# SF32LB57x register map
File version: 1.0
CPU: CM33 r0p1, little endian, MPU, FPU, 3 interrupt priority bits
Registers are 32-bit, read-write, reset 0x0 unless marked. A register's access mark holds for its fields unless they carry their own. Offsets are from the block's base; [hi:lo] are bit positions; {n}, {i} and the like mark numbered series; 'fields as' and 'values as' point back to an identical list.

## LCDC1
Base 0x50008000
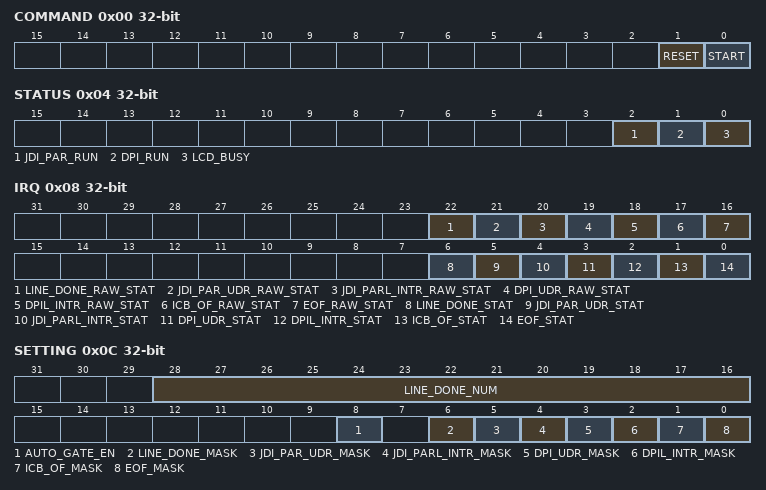
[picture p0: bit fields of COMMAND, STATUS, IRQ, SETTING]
0x00 COMMAND
  [1] RESET — 1: reset the whole graphics 0: release the reset
  [0] START — write 1 to trigger the lcd interface block
0x04 STATUS
  [2] JDI_PAR_RUN — JDI parallel interface is running
  [1] DPI_RUN — DPI interface is running
  [0] LCD_BUSY — LCS controll busy flag
0x08 IRQ
  [22] LINE_DONE_RAW_STAT — raw_status of line process done interrupt
  [21] JDI_PAR_UDR_RAW_STAT — raw_status of jdi parallel interface under run interrupt
  [20] JDI_PARL_INTR_RAW_STAT — raw_status of jdi parallel interface line interrupt
  [19] DPI_UDR_RAW_STAT — raw status of dpi under run interrupt
  [18] DPIL_INTR_RAW_STAT — raw status of dpi line interrupt
  [17] ICB_OF_RAW_STAT — raw status of icb overflow interrupt
  [16] EOF_RAW_STAT — raw status of end of frame interrupt
  [6] LINE_DONE_STAT — line process done interrupt, masked by mask register
  [5] JDI_PAR_UDR_STAT — jdi parallel interface under run interrupt, masked by mask register
  [4] JDI_PARL_INTR_STAT — jdi parallel interface line interrupt, masked by mask register
  [3] DPI_UDR_STAT — dpi under run interrupt, masked by mask register
  [2] DPIL_INTR_STAT — dpi line interrupt, masked by mask register
  [1] ICB_OF_STAT — icb overflow interrupt, masked by mask register
  [0] EOF_STAT — end of frame interrupt, masked by mask register
0x0C SETTING
  [28:16] LINE_DONE_NUM — line number of line process done interrupt
  [8] AUTO_GATE_EN — auto clock gating enable
  [6] LINE_DONE_MASK — line process done interrupt, 0: mask the interrupt
  [5] JDI_PAR_UDR_MASK — jdi parallel interface under run interrupt mask, 0: mask the interrupt
  [4] JDI_PARL_INTR_MASK — jdi parallel interface line interrupt, 0: mask the interrupt
  [3] DPI_UDR_MASK — dpi under run interrupt mask, 0: mask the interrupt
  [2] DPIL_INTR_MASK — dpi line interrupt, 0: mask the interrupt
  [1] ICB_OF_MASK — icb overflow interrupt mask, 0: mask the interrupt
  [0] EOF_MASK — end of frame interrupt mask, 0: mask the interrupt
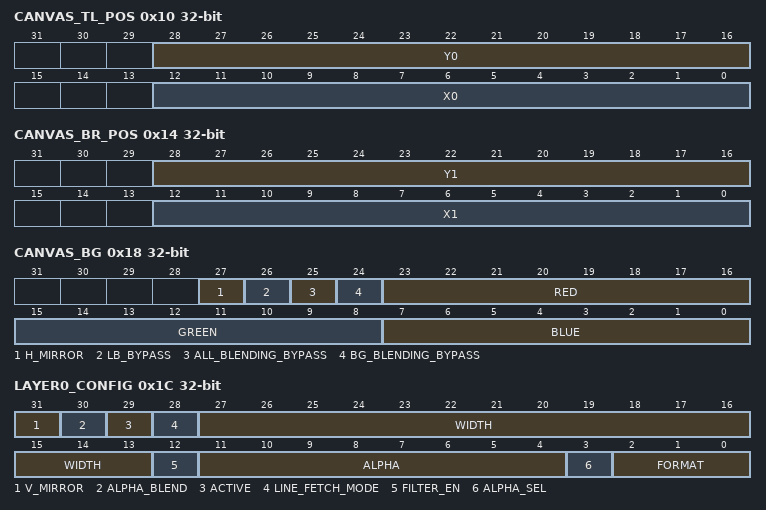
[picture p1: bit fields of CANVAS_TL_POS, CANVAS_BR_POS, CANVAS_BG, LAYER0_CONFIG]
0x10 CANVAS_TL_POS
  [28:16] Y0, [12:0] X0
0x14 CANVAS_BR_POS
  [28:16] Y1, [12:0] X1
0x18 CANVAS_BG
  [27] H_MIRROR — set 1 to do horizontal mirror for output image(not supported)
  [26] LB_BYPASS — line buffer bypass. Set 1 to bypass line buffer.
  [25] ALL_BLENDING_BYPASS — if this bit is set, lcdc is in pure dma mode. No blending operation.
  [24] BG_BLENDING_BYPASS — if this bit is set, the layer is not blending with background. The alpha value will be reserved to output.
  [23:16] RED — Red color
  [15:8] GREEN — green color
  [7:0] BLUE — blue color
0x1C LAYER0_CONFIG
  [31] V_MIRROR — set 1 to do vertical mirror for the layer
  [30] ALPHA_BLEND — set 1 to enable alpha blending mode. Use layer alpha as blending factor for image with Alpha. Alpha_out = Layer_alpha * Image_alpha
  [29] ACTIVE — layer active flag
  [28] LINE_FETCH_MODE — line fetch mode 0: address skip every single line 1: address skip every two line
  [27:13] WIDTH — source image width(including padding), unit is bytes
  [12] FILTER_EN — layer color filter enable
  [11:4] ALPHA — layer alpha value
  [3] ALPHA_SEL — alpha selection 1'b0: select alpha according to image format 1'b1: select layer alpha
  [2:0] FORMAT — overlay layer input format 3'h0: RGB565 3'h1: RGB888 3'h2: ARGB8888 3'h3: ARGB8565 3'h4: RGB332 3'h5: A8 3'h6: L8 others: reserved
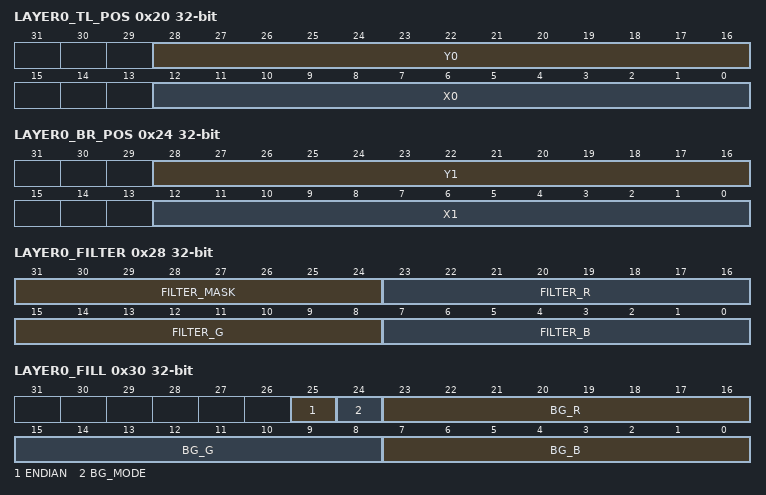
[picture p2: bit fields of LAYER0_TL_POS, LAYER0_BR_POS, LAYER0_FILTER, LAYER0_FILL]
0x20 LAYER0_TL_POS
  [28:16] Y0 — Coordingate Y-value
  [12:0] X0 — Coordinate X-value
0x24 LAYER0_BR_POS
  [28:16] Y1 — Coordingate Y-value
  [12:0] X1 — Coordinate X-value
0x28 LAYER0_FILTER
  [31:24] FILTER_MASK — layer color filter mask
  [23:16] FILTER_R — filter r color
  [15:8] FILTER_G — filter g color
  [7:0] FILTER_B — filter b color
0x2C LAYER0_SRC
  [31:0] ADDR — source image RGB data address[31:0]. For RGB565 format, address should be aligned to halfword. For ARGB8888 format, address should be aligned to word.
0x30 LAYER0_FILL
  [25] ENDIAN — input 565 data format endian 0: {R[4:0], G[5:3], G[2:0], B[4:0]} 1: {G[2:0], R[4:0], B[4:0], G[5:3]}
  [24] BG_MODE — not used
  [23:16] BG_R — background r color
  [15:8] BG_G — background g color
  [7:0] BG_B — background b color
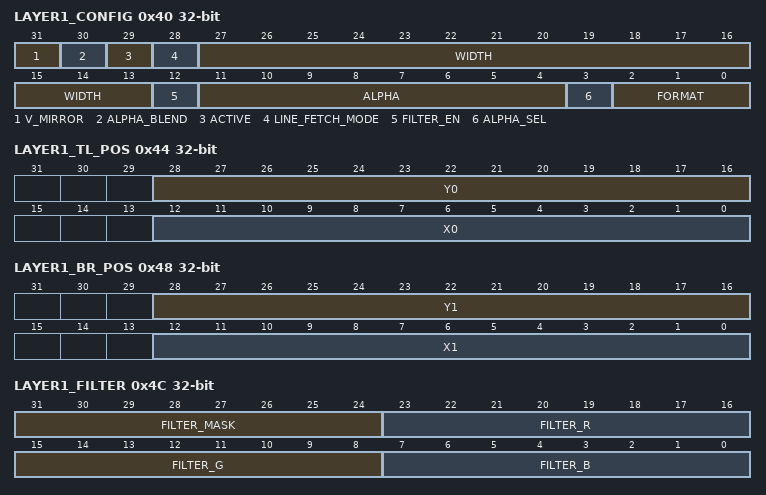
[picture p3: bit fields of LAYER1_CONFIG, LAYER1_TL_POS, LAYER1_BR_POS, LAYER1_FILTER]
0x40 LAYER1_CONFIG
  fields as LAYER0_CONFIG
0x44 LAYER1_TL_POS
  [28:16] Y0 — Coordingate Y-value
  [12:0] X0 — Coordinate X-value
0x48 LAYER1_BR_POS
  [28:16] Y1 — Coordingate Y-value
  [12:0] X1 — Coordinate X-value
0x4C LAYER1_FILTER
  fields as LAYER0_FILTER
0x50 LAYER1_SRC
  fields as LAYER0_SRC
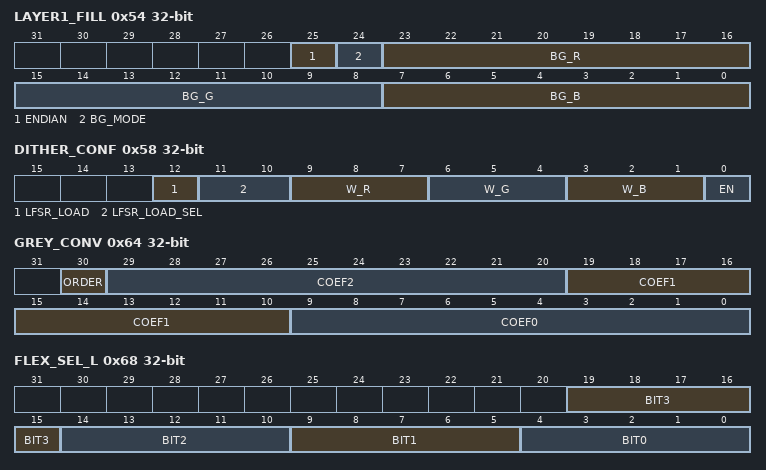
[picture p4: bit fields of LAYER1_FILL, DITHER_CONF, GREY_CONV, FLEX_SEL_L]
0x54 LAYER1_FILL
  fields as LAYER0_FILL
0x58 DITHER_CONF
  [12] LFSR_LOAD — load lfsr init value
  [11:10] LFSR_LOAD_SEL — select lfsr 0: none 1: red 2: green 3: blue
  [9:7] W_R — red dither width
  [6:4] W_G — green dither width
  [3:1] W_B — blue dither width
  [0] EN — dither enable
0x5C DITHER_LFSR
  [31:0] INIT_VAL — lfsr init load value
0x60 CONV_CFG
  [2:0] FORMAT — CANVAS conversion format: 0: ARGB 1: G8 2: G4 3: G2 4: F8 5: F4 6: F2
0x64 GREY_CONV
  [30] ORDER — G4 format bit order 1'h0: byteG4 = {p1, p0}, byteG2 = {p3,p2,p1,p0} 1'h1: byteG4 = {p0, p1}, byteG2 = {p0,p1,p2,p3}
  [29:20] COEF2
  [19:10] COEF1
  [9:0] COEF0 — grey = (coef0 * r + coef1 * g + coef2 * b) >> 10
0x68 FLEX_SEL_L
  [19:15] BIT3
  [14:10] BIT2
  [9:5] BIT1
  [4:0] BIT0 — bit select index from internal ARGB8888 format data
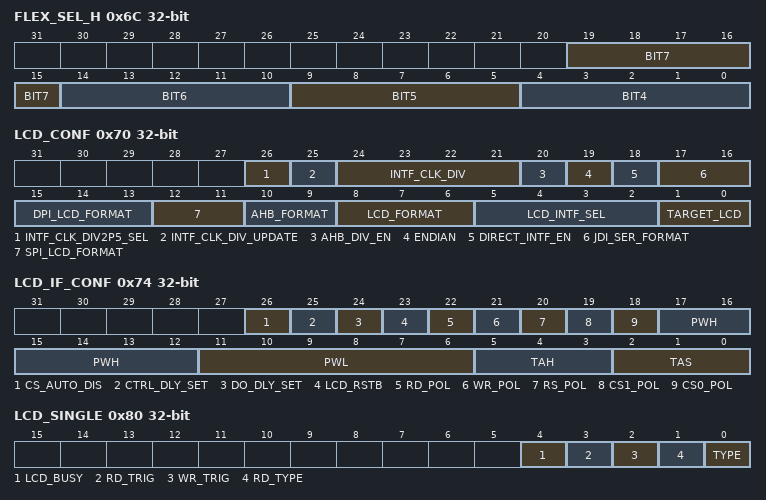
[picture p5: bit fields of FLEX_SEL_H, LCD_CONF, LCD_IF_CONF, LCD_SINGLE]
0x6C FLEX_SEL_H
  [19:15] BIT7
  [14:10] BIT6
  [9:5] BIT5
  [4:0] BIT4 — bit select index from internal ARGB8888 format data
0x70 LCD_CONF
  [26] INTF_CLK_DIV2P5_SEL — write 1 to select 2.5 divider value for interface clock
  [25] INTF_CLK_DIV_UPDATE — write 1 to update lcd interface clock divider value.
  [24:21] INTF_CLK_DIV — lcd interface clock divider value. minimum value is 1.
  [20] AHB_DIV_EN — set 1 to divide AHB undefined length burst to fix length burst
  [19] ENDIAN — LCD 565 data format endian, this bit would affect SPI, DPI, DBI and AHB interface 565 format 0: {R[4:0], G[5:3], G[2:0], B[4:0]} 1: {G[2:0], R[4:0], B[4:0], G[5:3]}
  [18] DIRECT_INTF_EN — when the target LCD is AHB LCD, this bit enable the direct interface to DSI module. Direct interface has higher bandwidth and speed than AHB interface.
  [17:16] JDI_SER_FORMAT — JDI serial format 2'b00: 3-bit mode 2'b01: 4-bit mode 2'b10: 1-bit mode 2'b11: reserved
  [15:13] DPI_LCD_FORMAT — DPI LCD format 3'b000: 16-bit conf1 3'b001: 16-bit conf2 3'b010: 16-bit conf3 3'b011: 18-bit conf1 3'b100: 18-bit conf2 3'b101: 24-bit 3'b110: 18-bit over 8-bit bus 3'b111: 24-bit over 8-bit bus others: Reserved
  [12:11] SPI_LCD_FORMAT — SPI LCD format 2'b00: 8-bit RGB 3:3:2 2'b01: 16-bit RGB 5:6:5 2'b10: 24-bit RGB 8:8:8 2'b11: 8-bit mode(lowest 8 bit mode)
  [10:9] AHB_FORMAT — AHB LCD/RAM output format: 0: RGB565 1: RGB888 2: ARGB8888 3: RGB332
  [8:6] LCD_FORMAT — LCD output format: 3'b000: 8-bit RGB 3:3:2 3'b001: 16-bit RGB 5:6:5 over 8-bit bus, 2 cycles/pixel 3'b010: 12-bit RGB 4:4:4 3'b011: 16-bit RGB 5:6:5 3'b100: 18-bit RGB 6:6:6 3'b101: 24-bit RGB 8:8:8 3'b110: 24-bit RGB 8:8:8 over 16-bit bus, 1.5 cycles/pixel 3'b111: 24-bit RGB 8:8:8 over 8-bit bus, 3cycles/pixel others: Reserved
  [5:2] LCD_INTF_SEL — 4'h0: 8080 DBI Type B 4'h1: SPI interface 4'h2: DBI to DSI interface 4'h3: DPI interface 4'h4: JDI serial interface 4'h5: JDI parallel interface 4'h6: 8080 DBI Type A 4'h7: DPI to DSI interface 4'h8: Timing Controller Interface other: reserved
  [1:0] TARGET_LCD — The Data can be sent to four destinations: 2'b00: LCD panel 0 2'b01: LCD panel 1 2'b10: AHB LCD 2'b11: AHB RAM
0x74 LCD_IF_CONF
  [26] CS_AUTO_DIS — 1: CS is automatically disabled after data transaction 0: CS is not disabled after data transaction
  [25] CTRL_DLY_SET — if this bit is set to 1, LCD control output will be delayed for 1 lcdc clock cycle
  [24] DO_DLY_SET — if this bit is set to 1, LCD data output will be delayed for 1 lcdc clock cycle
  [23] LCD_RSTB — LCD RSTB pin, direct to output
  [22] RD_POL — LCD RD pin polarity. RD is 0 for write operation, 1 for idle if polarity bit is set as 0. RD bit definition is opposite if polarity bit is set as 1.
  [21] WR_POL — LCD WR pin polarity. WR is 0 for write operation, 1 for idle if polarity bit is set as 0. WR bit definition is opposite if polarity bit is set as 1.
  [20] RS_POL — LCD RS pin polarity. RS is 1 for data access, 0 for command access if polarity bit is set as 0. RS bit definition is opposite if polarity bit is set as 1.
  [19] CS1_POL — LCD0 CS pin polarity. CS is 0 for LCD chip select if polarity bit is set as 0. CS bit definition is opposite if polarity bit is set as 1.
  [18] CS0_POL — LCD1 CS pin polarity. CS is 0 for LCD chip select if polarity bit is set as 0. CS bit definition is opposite if polarity bit is set as 1.
  [17:12] PWH — inactive cycles of LCD_WR/LCD_RD for consecutive write/read operation
  [11:6] PWL — active cycles of LCD_WR/LCD_RD
  [5:3] TAH — hold cycles, delay from LCD_WR/LCD_RD inactive to LCD_CS inactive
  [2:0] TAS — setup cycles, delay from LCD_CS active to LCD_WR/LCD_RD active
0x78 LCD_MEM
  [31:0] ADDR — address for AHB LCD/AHB RAM
0x7C LCD_O_WIDTH
  [15:0] OFFSET — AHB RAM address offset for each line
0x80 LCD_SINGLE
  [4] LCD_BUSY — LCD/SPI LCD interface is busy for single access
  [3] RD_TRIG — Single read operation trigger
  [2] WR_TRIG — Single write operation trigger
  [1] RD_TYPE — LCD access type during read data phase 1'h0: command 1'h1: data
  [0] TYPE — LCD access type, this bit could affect all LCD interface including SPI, parellel and AHB 1'b0: command 1'b1: data
0x84 LCD_WR
  [31:0] DATA — LCD write data
0x88 LCD_RD
  [31:0] DATA — LCD read data
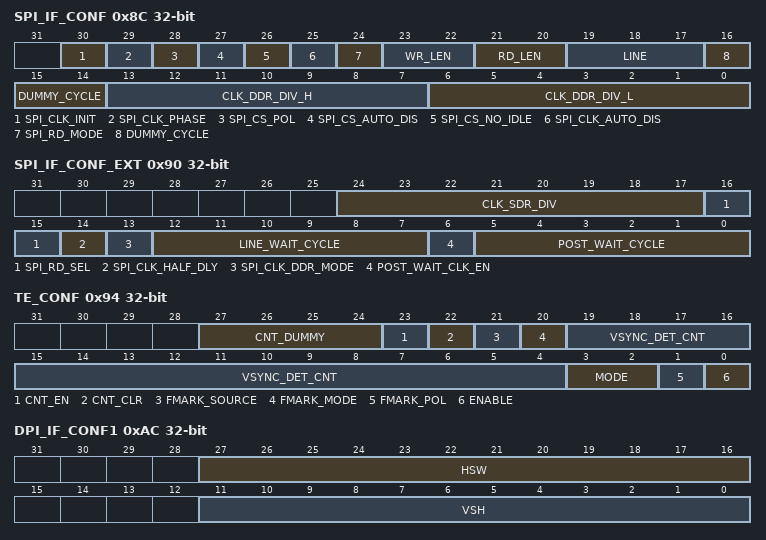
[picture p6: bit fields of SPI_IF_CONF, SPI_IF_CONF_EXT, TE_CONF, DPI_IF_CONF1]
0x8C SPI_IF_CONF
  [30] SPI_CLK_INIT — SPI CLK idle state value 1'h0: high 1'h1: low
  [29] SPI_CLK_PHASE — SPI CLK phase 1'h0: 1st edge for data capture 1'h1: 2nd edge for data capture
  [28] SPI_CS_POL — SPI CS polarity 0: low active 1: high active
  [27] SPI_CS_AUTO_DIS — 1: SPI CS is automatically disabled after data transaction 0: SPI CS is not disabled after data transaction
  [26] SPI_CS_NO_IDLE — 1: SPI CS is always active during data transaction 0: SPI CS is IDLE in wait state during data transaction
  [25] SPI_CLK_AUTO_DIS — 1: SPI clock auto disable in wait state during data transaction 0: SPI clock is always on in wait state during data transaction
  [24] SPI_RD_MODE — SPI read mode: 1'b0: normal read. Send write request before read. 1'b1: direct read. Read data without write request.
  [23:22] WR_LEN — SPI write data length(single access)
  [21:20] RD_LEN — SPI read data length(single access)
  [19:17] LINE — SPI line mode 0: 4-line 1: 4-line with 2 data line(support RGB565 and RGB888) 2: 4-line with 4 data line(support RGB565 and RGB888) 3: reserved 4: 3-line 5: 3-line with 2 data line(support RGB565 and RGB888) 6: 3-line with 4 data line(support RGB565 and RGB888) 7: reserved
  [16:14] DUMMY_CYCLE — SPI transaction dummy cycle
  [13:7] CLK_DDR_DIV_H — SPI clock ddr mode divider high cycle count, minimum value is 1
  [6:0] CLK_DDR_DIV_L — SPI clock ddr mode divider low cycle count, minimum value is 1
0x90 SPI_IF_CONF_EXT
  [24:17] CLK_SDR_DIV — SPI clock sdr mode divider value, minimum value is 1.
  [16:15] SPI_RD_SEL — SPI read line select. 0: select line 0 1: select line 1 2: select line 2 3: select line 3
  [14] SPI_CLK_HALF_DLY — delay SPI clock for half lcd clock. This option is used for odd spi clock divider value.
  [13] SPI_CLK_DDR_MODE — SPI CLK DDR mode 1'h0: SDR mode 1'h1: DDR mode
  [12:7] LINE_WAIT_CYCLE — SPI line wait cycle, wait cycle is after each line and is according to SPI clock. 0 refers to no wait cycle.
  [6] POST_WAIT_CLK_EN — SPI clock enable during post wait cycle
  [5:0] POST_WAIT_CYCLE — SPI wait cycle after last pixel, wait cycle is according to SPI clock. 0 refers to no wait cycle.
0x94 TE_CONF
  [27:24] CNT_DUMMY — dummy TE triggers after CNT_EN is set. Skip the first CNT_DUMMY TE triggers, then start TE counter.
  [23] CNT_EN — enable TE counter for window mode
  [22] CNT_CLR — clear TE counter for window mode
  [21] FMARK_SOURCE — TE signal source 1: use TE signal from DSI 0: use TE signal from external pin
  [20] FMARK_MODE — TE signal trigger mode 1: edge trigger 0: pulse trigger
  [19:4] VSYNC_DET_CNT — vsync signal detect counter, used for mode 1 to detect vsync signal
  [3:2] MODE — 0: vsync only TE mode 1: vsync+hsync TE mode 2: window TE mode
  [1] FMARK_POL — TE signal polarity
  [0] ENABLE — TE enable
0x98 TE_CONF2
  [31:0] DLY_CNT0 — TE delay counter0, used for vsync and vsync+hsync mode
0x9C TE_CONF3
  [31:0] DLY_CNT1 — TE delay counter1, used for window mode TE window is active when (te_cnt lte cnt0 || te_cnt >= cnt1) and and te_cnt >= cnt2
0xA0 TE_CONF4
  [31:0] DLY_CNT2 — TE delay counter2, used for window mode TE window is active when (te_cnt lte cnt0 || te_cnt >= cnt1) and and te_cnt >= cnt2
0xA4 TE_STAT
  [31:0] TE_C_CNT — current TE counter for window mode
0xA8 TE_STAT2
  [31:0] TE_MAX_CNT — max TE counter value for window mode
0xAC DPI_IF_CONF1
  [27:16] HSW — dpi hsync width
  [11:0] VSH — dpi vsync height
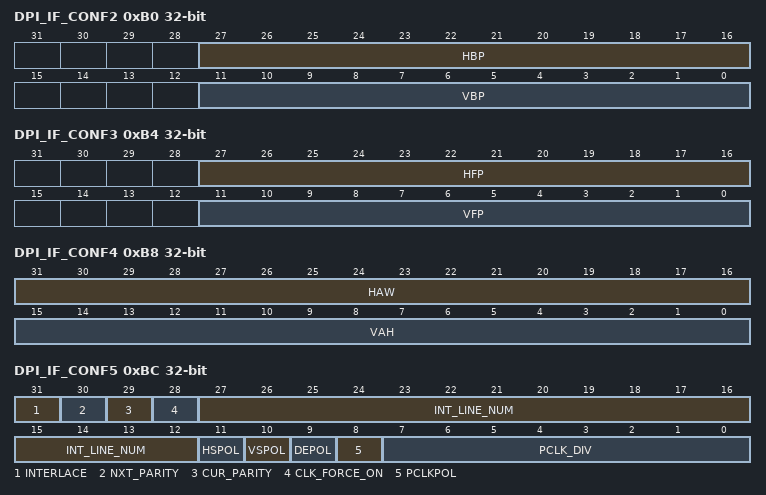
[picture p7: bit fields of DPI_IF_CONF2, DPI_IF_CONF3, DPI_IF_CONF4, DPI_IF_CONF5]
0xB0 DPI_IF_CONF2
  [27:16] HBP — horizontal back porch
  [11:0] VBP — vertical back porch
0xB4 DPI_IF_CONF3
  [27:16] HFP — horizontal front porch
  [11:0] VFP — vertical front porch
0xB8 DPI_IF_CONF4
  [31:16] HAW — horizontal active width
  [15:0] VAH — vertical active height
0xBC DPI_IF_CONF5
  [31] INTERLACE — 1: interlace mode 0: non interlace mode
  [30] NXT_PARITY — parity for next frame in interlace mode 1: odd 0: even
  [29] CUR_PARITY — parity for current frame in interlace mode 1: odd 0: even
  [28] CLK_FORCE_ON — 1: force DPI clock on 0: DPI clock is controlled by hardware
  [27:12] INT_LINE_NUM — DPI interrupt line number
  [11] HSPOL — hsync polarity
  [10] VSPOL — vsync polarity
  [9] DEPOL — de polarity
  [8] PCLKPOL — pixel clock polarity
  [7:0] PCLK_DIV — pixel clock divider(minimum is 2)
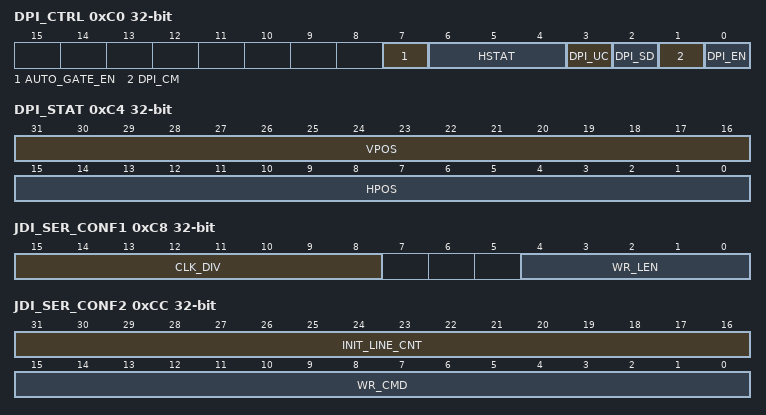
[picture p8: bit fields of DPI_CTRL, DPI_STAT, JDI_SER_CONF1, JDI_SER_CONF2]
0xC0 DPI_CTRL
  [7] AUTO_GATE_EN — dpi clock auto gating when underrun is detected 1: enable dpi clock auto gating function 0: disable dpi clock auto gating function
  [6:4] HSTAT — horizontal status 0: idle 1: prep 2: hsync 3: hbp 4: hact 5: hfp 6: wait
  [3] DPI_UC — dpi update config
  [2] DPI_SD — dpi shutdown
  [1] DPI_CM — dpi color mode
  [0] DPI_EN — dpi interface enable
0xC4 DPI_STAT
  [31:16] VPOS — dpi vertical position
  [15:0] HPOS — dpi horizontal position
0xC8 JDI_SER_CONF1
  [15:8] CLK_DIV — jdi serial clock divider(minimum is 2)
  [4:0] WR_LEN — jdi single write bit length
0xCC JDI_SER_CONF2
  [31:16] INIT_LINE_CNT — jdi serial init line counter
  [15:0] WR_CMD — jdi serial data transfer write command
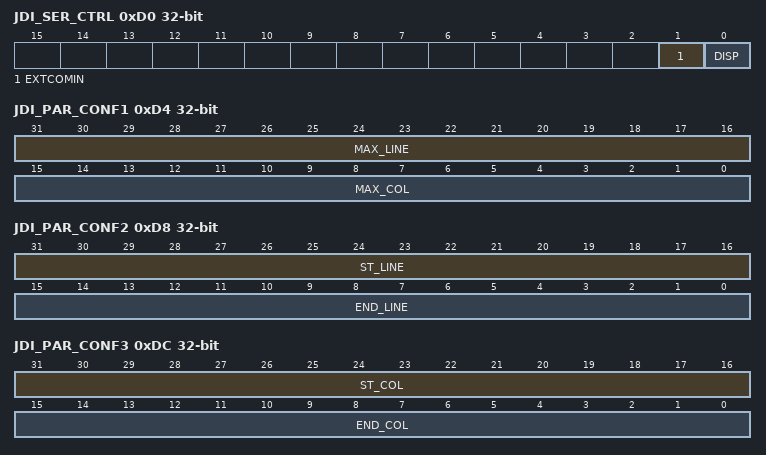
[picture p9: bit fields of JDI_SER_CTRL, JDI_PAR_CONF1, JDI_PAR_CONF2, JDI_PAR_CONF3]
0xD0 JDI_SER_CTRL
  [1] EXTCOMIN — jdi serial interface extcomin control
  [0] DISP — jdi serial interface disp control
0xD4 JDI_PAR_CONF1
  [31:16] MAX_LINE — jdi parallel interface max line, line number start from 0
  [15:0] MAX_COL — jdi parallel interface max column, column number start from 0
0xD8 JDI_PAR_CONF2
  [31:16] ST_LINE — jdi parallel interface start line, line number start from 0
  [15:0] END_LINE — jdi parallel interface end line, line number start from 0
0xDC JDI_PAR_CONF3
  [31:16] ST_COL — jdi parallel interface start column, column number start from 0
  [15:0] END_COL — jdi parallel interface end column, column number start from 0
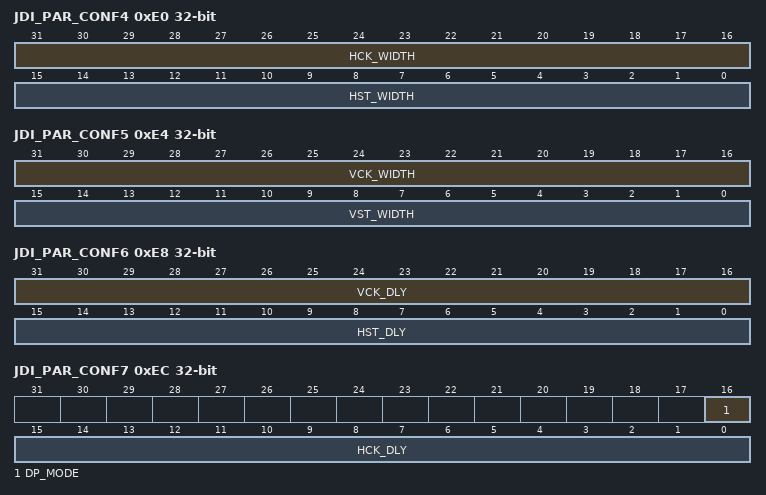
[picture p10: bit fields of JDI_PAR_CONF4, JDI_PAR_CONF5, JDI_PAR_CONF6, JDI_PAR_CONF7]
0xE0 JDI_PAR_CONF4
  [31:16] HCK_WIDTH — jdi parallel interface HCK width, HSK width = lcd_ck_cycle * HCK_WIDTH
  [15:0] HST_WIDTH — jdi parallel interface HST width, HST width = lcd_ck_cycle * HST_WIDTH
0xE4 JDI_PAR_CONF5
  [31:16] VCK_WIDTH — jdi parallel interface VCK width, VCK width = lcd_ck_cycle * VCK_WIDTH
  [15:0] VST_WIDTH — jdi parallel interface VST width, VST width = lcd_ck_cycle * VST_WIDTH
0xE8 JDI_PAR_CONF6
  [31:16] VCK_DLY — jdi parallel interface VST to VCK delay, VST2VCK delay = lcd_ck_cycle * VCK_DLY
  [15:0] HST_DLY — jdi parallel interface VCK to HST delay, VCK2HST delay = lcd_ck_cycle * HST_DLY
0xEC JDI_PAR_CONF7
  [16] DP_MODE — double pixel mode. Some jdi parallel screens use large pixel+small pixel structure. Set this bit to 1 to support this structure.
  [15:0] HCK_DLY — jdi parallel interface HST to HCK delay
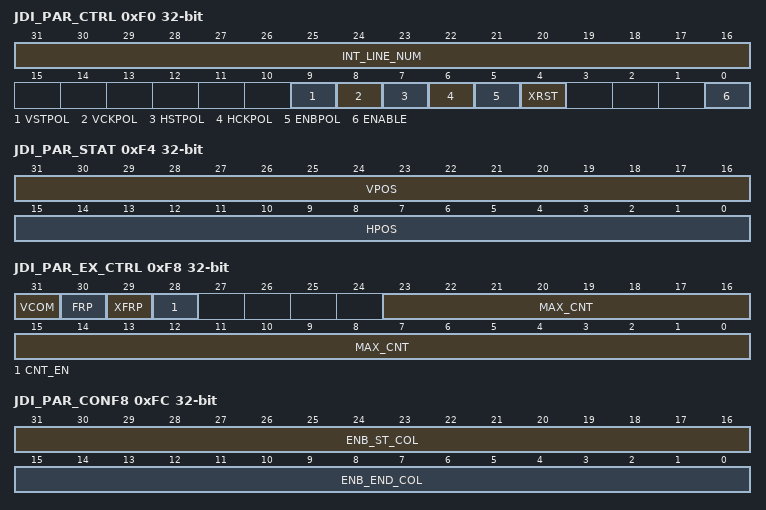
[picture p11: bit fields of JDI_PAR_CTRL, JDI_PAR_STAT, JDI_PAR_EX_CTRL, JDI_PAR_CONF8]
0xF0 JDI_PAR_CTRL
  [31:16] INT_LINE_NUM — jdi parallel interface interrupt line number, line number start from 0.
  [9] VSTPOL — jdi parallel vst polarity
  [8] VCKPOL — jdi parallel vck polarity
  [7] HSTPOL — jdi parallel hst polarity
  [6] HCKPOL — jdi parallel hck polarity
  [5] ENBPOL — jdi parallel enb polarity
  [4] XRST — jdi parallel interface XRST
  [0] ENABLE — jdi parallel interface enable
0xF4 JDI_PAR_STAT
  [31:16] VPOS — jdi parallel vertical position
  [15:0] HPOS — jdi parallel horizontal position
0xF8 JDI_PAR_EX_CTRL
  [31] VCOM — VCOM value
  [30] FRP — FRP value
  [29] XFRP — XFRP value
  [28] CNT_EN — VCOM/FRP/XFRP counter enable
  [23:0] MAX_CNT — VCOM/FRP/XFRP max counter
0xFC JDI_PAR_CONF8
  [31:16] ENB_ST_COL — jdi parallel interface enb start column, column number start from 0
  [15:0] ENB_END_COL — jdi parallel interface enb end column, column number start from 0
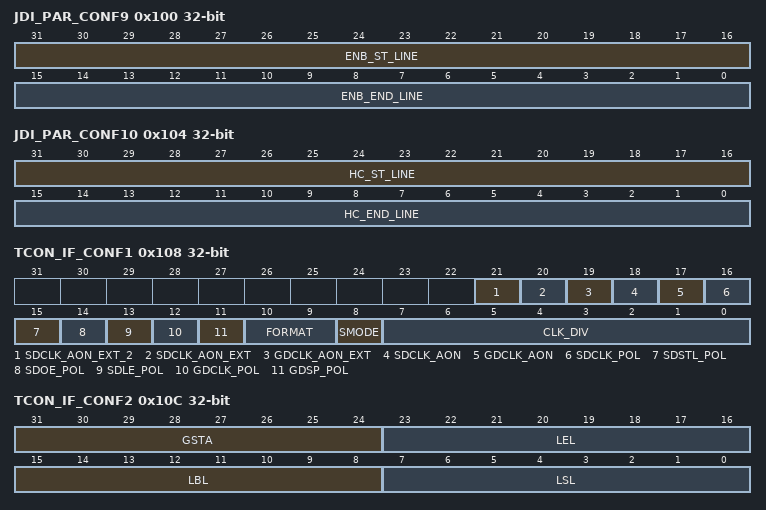
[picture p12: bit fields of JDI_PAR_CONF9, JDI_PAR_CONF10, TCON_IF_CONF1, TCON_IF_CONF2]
0x100 JDI_PAR_CONF9
  [31:16] ENB_ST_LINE — jdi parallel interface enb start line, line number start from 0
  [15:0] ENB_END_LINE — jdi parallel interface enb end line, line number start from 0
0x104 JDI_PAR_CONF10
  [31:16] HC_ST_LINE — jdi parallel interface horizontal control start line, line number start from 0
  [15:0] HC_END_LINE — jdi parallel interface horizontal control end line, line number start from 0
0x108 TCON_IF_CONF1
  [21] SDCLK_AON_EXT_2 — 1: keep sdclk on during FSL stage
  [20] SDCLK_AON_EXT — 1: keep sdclk on during FBL stage
  [19] GDCLK_AON_EXT — 1: keep gdclk on during FBL stage
  [18] SDCLK_AON — 1: keep sdclk on during FEL stage
  [17] GDCLK_AON — 1: keep gdclk on during FEL stage
  [16] SDCLK_POL
  [15] SDSTL_POL
  [14] SDOE_POL
  [13] SDLE_POL
  [12] GDCLK_POL
  [11] GDSP_POL
  [10:9] FORMAT — data format: 0: 8bit mode 1: 16bit mode other: reserved
  [8] SMODE — smode selection
  [7:0] CLK_DIV — timing controller clock divider(minimum is 2)
0x10C TCON_IF_CONF2
  [31:24] GSTA, [23:16] LEL, [15:8] LBL, [7:0] LSL
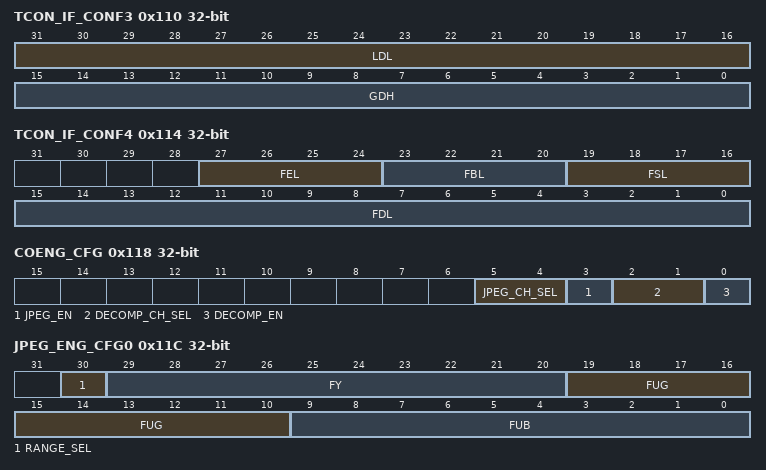
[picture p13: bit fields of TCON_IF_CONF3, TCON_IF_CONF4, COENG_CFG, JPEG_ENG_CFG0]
0x110 TCON_IF_CONF3
  [31:16] LDL, [15:0] GDH
0x114 TCON_IF_CONF4
  [27:24] FEL, [23:20] FBL, [19:16] FSL, [15:0] FDL
0x118 COENG_CFG
  [5:4] JPEG_CH_SEL — jpeg engine channel select 2'h0: OL0 2'h1: OL1 2'h2, 2'h3: reserved
  [3] JPEG_EN — jpeg enable
  [2:1] DECOMP_CH_SEL — decompression channel select 2'h0: OL0 2'h1: OL1 2'h2, 2'h3: reserved
  [0] DECOMP_EN — decompression enable
0x11C JPEG_ENG_CFG0
  [30] RANGE_SEL — yuv input range 1'h0: tv range 1'h1: pc range
  [29:20] FY — YUV Fy coef
  [19:10] FUG — YUV Fug coef
  [9:0] FUB — YUV Fub coef
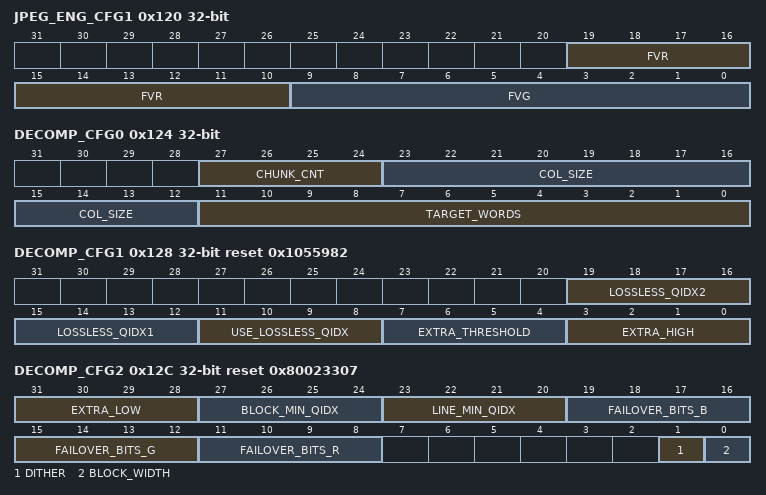
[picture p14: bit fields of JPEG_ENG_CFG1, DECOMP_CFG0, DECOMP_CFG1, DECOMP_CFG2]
0x120 JPEG_ENG_CFG1
  [19:10] FVR — YUV Fvr coef
  [9:0] FVG — YUV Fvg coef
0x124 DECOMP_CFG0
  [27:24] CHUNK_CNT — number of chunks for each image line
  [23:12] COL_SIZE — number of pixels for each chunk
  [11:0] TARGET_WORDS — Input size of data for each chunk before decompression. Each chunk has target_words*3*2 bytes data. Total data size of each line before decompression target_words*chunk_cnt*3*2 bytes.
0x128 DECOMP_CFG1 reset 0x1055982
  [19:16] LOSSLESS_QIDX2 — condition to decrease qidx
  [15:12] LOSSLESS_QIDX1 — up level for adjusted qidx value for low quality block
  [11:8] USE_LOSSLESS_QIDX — condition to increase qidx
  [7:4] EXTRA_THRESHOLD — the threshold to distinguish high/low quality block
  [3:0] EXTRA_HIGH — extra bit for high quality bit
0x12C DECOMP_CFG2 reset 0x80023307
  [31:28] EXTRA_LOW — extra bit for low quality block
  [27:24] BLOCK_MIN_QIDX — minimum qidx for block mode
  [23:20] LINE_MIN_QIDX — minimum qidx for line mode
  [19:16] FAILOVER_BITS_B — failover compression mode target bits(Blue)
  [15:12] FAILOVER_BITS_G — failover compression mode target bits(Green)
  [11:8] FAILOVER_BITS_R — failover compression mode target bits(Red)
  [1] DITHER — dithering function 0: off 1: on
  [0] BLOCK_WIDTH — block_size in pixel unit. 0: 16 pixels 1: 32 pixels Small block size will cause more blocks and more bits to store block information.
0x130 DECOMP_STAT
  [6:0] BUF_MAX_DEPTH — buf max usage
0x134 PERF_CNT
  [31:0] VAL — lcdc performance counter
0x138 LINE_BUF0
  [31:2] ADDR — line buffer0 address
0x13C LINE_BUF1
  [31:2] ADDR — line buffer0 address
0x140 CANVAS_STAT0
  [28:16] Y_COR — current lcdc engine y cordinate. start from canvas_tl_y + 1 to canvas_br_y + 1. Check this to figure where the epic engine is stucked.
  [12:0] X_COR — current lcdc engine x cordinate. start from canvas_tl_x to canvas_br_x. Check this to figure where the epic engine is stucked.
0x144 CANVAS_STAT1
  [11:9] FETCH_STAT — fetch status
  [8:6] PREC_STAT — prec status
  [5:3] POSTC_STAT — postc_status
  [2:0] FIFO_CNT — pre calc fifo count
0x148 OL0_STAT
  [10:8] PF_PR, [7:6] PF_DF, [5:4] DATA_CONV, [3:2] PREFETCH_READ, [1] PREFETCH_OUT, [0] DONE_REQ
0x14C OL1_STAT
  fields as OL0_STAT
0x150 MEM_IF_STAT
  [19:17] ARB_MAIN_B, [16:14] ARB_READ_PORT_B, [13:10] AHB_B, [9:7] ARB_MAIN_A, [6:4] ARB_READ_PORT_A, [3:0] AHB_A
0x154 TE_WIDTH_CNT0
  [31] EN — 1: enable counter counter clock is 1/256 *lcdc sysclk
  [30] EDGE — counter check edge 0: rising edge 1: falling edge
  [29:22] RSVD — TE high count
  [21] VALID — 1: total counter value is valid
  [20] OVERFLOW — 1: total counter overflow
  [19:0] CYCLE — total clock counter value of two TE edge
0x158 TE_WIDTH_CNT1
  [21] VALID — 1: high counter value is valid
  [20] OVERFLOW — 1: high counter overflow
  [19:0] HIGH — TE high cycle counter value
0x15C DPI_FRAME_CNT
  [31] EN — 1: enable counter counter clock is 1/256 *lcdc sysclk
  [30] EDGE — counter check edge 0: rising edge 1: falling edge
  [21] VALID — 1: total counter value is valid
  [20] OVERFLOW — 1: total counter overflow
  [19:0] CYCLE — total clock cycle counter of two vsync edge
